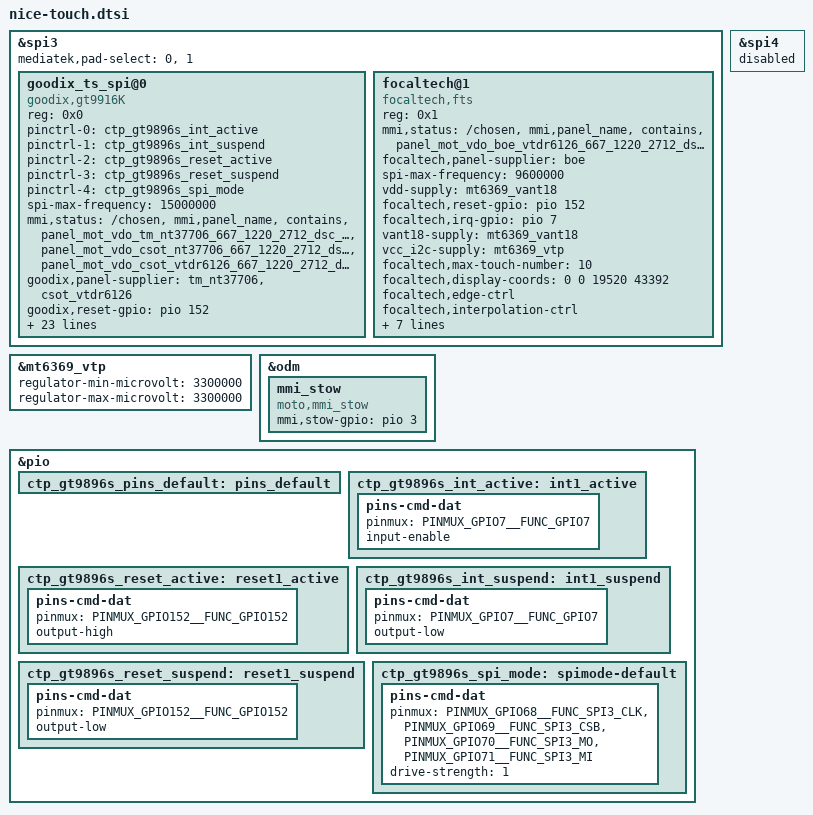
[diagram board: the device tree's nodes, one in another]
// SPDX-License-Identifier: (GPL-2.0 OR MIT)
/*
 * Copyright (C) 2020 MediaTek Inc.
 */

/* TOUCH start */
&spi3 {
	status = "okay";
	#address-cells = <1>;
	#size-cells = <0>;
	mediatek,pad-select = <0>, <1>;

	goodix_ts_spi@0 {
		status = "okay";
		compatible = "goodix,gt9916K";
		reg = <0x0>;
		pinctrl-names = "pmx_ts_active", "pmx_ts_suspend", "stylus_clk_active", "stylus_clk_suspend","gt9916_spi_mode";
		pinctrl-0 = <&ctp_gt9896s_int_active>;
		pinctrl-1 = <&ctp_gt9896s_int_suspend>;
		pinctrl-2 = <&ctp_gt9896s_reset_active>;
		pinctrl-3 = <&ctp_gt9896s_reset_suspend>;
		pinctrl-4 = <&ctp_gt9896s_spi_mode>;
		spi-max-frequency = <15000000>;  /* 4800000,9600000,15000000,19200000 */
		mmi,status = "/chosen","mmi,panel_name","contains","panel_mot_vdo_tm_nt37706_667_1220_2712_dsc_dphy_nice","panel_mot_vdo_csot_nt37706_667_1220_2712_dsc_dphy_nice","panel_mot_vdo_csot_vtdr6126_667_1220_2712_dsc_dphy_nice";
		goodix,panel-supplier = "tm_nt37706","csot_vtdr6126";
		goodix,reset-gpio = <&pio 152 0x0>;
		goodix,irq-gpio = <&pio 7 0x2002>;
		goodix,avdd-name = "vtp";
//		goodix,avdd-gpio = <&pio 189 0x0>;
		vtp-supply = <&mt6369_vtp>;
		goodix,iovdd-name = "vant18";
//		goodix,iovdd-gpio = <&pio 114 0x0>;
		vant18-supply = <&mt6369_vant18>;
		goodix,irq-flags = <0x2002>; /* 1:trigger rising, 2:trigger falling;*/
		goodix,panel-max-id = <10>;
		goodix,panel-max-x = <19520>;
		goodix,panel-max-y = <43392>;
		goodix,panel-max-w = <256>;
		goodix,panel-max-p = <256>;
		goodix,edge-ctrl;
		goodix,sample-ctrl;
		goodix,interpolation-ctrl;
		goodix,gesture-wait-pm;
		goodix,stowed-mode-ctrl;
		goodix,pocket-mode-ctrl;
		/*goodix,config-name = "goodix_gt9916k_cfg_group.bin";
		goodix,firmware-name = "goodix_gt9916k_firmware.bin";*/
		mmi,enable-gestures;
		mmi,power-off-suspend;
		mmi,usb-charger-detection;
		mmi,supported_gesture_type = <0x07>;
		mmi,resolution_boost = <16>;
		mtk-charger = <&mt6375_chg>;
	};

	focaltech@1{
		status = "okay";
		compatible = "focaltech,fts";
		reg = <0x1>;
		mmi,status = "/chosen","mmi,panel_name","contains","panel_mot_vdo_boe_vtdr6126_667_1220_2712_dsc_dphy_nice";
		focaltech,panel-supplier = "boe";
		spi-max-frequency = <9600000>;
//		focaltech,vdd-gpio = <&pio 183 0x0>;
		vdd-supply= <&mt6369_vant18>;
		focaltech,reset-gpio = <&pio 152 0x0>;
		focaltech,irq-gpio = <&pio 7 0x2002>;
		vant18-supply = <&mt6369_vant18>;
//		vtp-supply = <&mt6369_vtp>;
		vcc_i2c-supply = <&mt6369_vtp>;
		focaltech,max-touch-number = <10>;
		focaltech,display-coords =  <0 0 19520 43392>;
		focaltech,edge-ctrl;
		focaltech,interpolation-ctrl;
		focaltech,sample-ctrl;
		fts,pocket-mode-ctrl;
		pinctrl-names = "pmx_ts_active", "pmx_ts_suspend", "pmx_ts_release";
		pinctrl-0 = <&ctp_gt9896s_int_active>;
		pinctrl-1 = <&ctp_gt9896s_int_suspend>;
		//panel = <&mot_tm_icna3508_ft3683g_667_1080x2400_dsc_vid &mot_boe_vtdr6130a_ft3683g_667_1080x2400_dsc_cmd>;
		//mmi,usb-charger-detection;
		mmi,enable-gestures;
		mmi,supported_gesture_type = <0x07>;
		focaltech,stowed-mode-ctrl;
	};
};

&mt6369_vtp {
	regulator-min-microvolt = <3300000>;
	regulator-max-microvolt = <3300000>;
};

&odm {
	mmi_stow: mmi_stow {
		compatible = "moto,mmi_stow";
		mmi,stow-gpio = <&pio 3 0x0>;
	};
};

&spi4 {
	status = "disabled";
};

&pio {
	ctp_gt9896s_pins_default: pins_default {
	};
	ctp_gt9896s_int_active: int1_active {
		pins-cmd-dat {
			pinmux = <PINMUX_GPIO7__FUNC_GPIO7>;
			input-enable;
		};
	};
	ctp_gt9896s_reset_active: reset1_active {
		pins-cmd-dat {
			pinmux = <PINMUX_GPIO152__FUNC_GPIO152>;
			output-high;
		};
	};
	ctp_gt9896s_int_suspend: int1_suspend {
		pins-cmd-dat {
			pinmux = <PINMUX_GPIO7__FUNC_GPIO7>;
			output-low;
		};
	};
	ctp_gt9896s_reset_suspend: reset1_suspend {
		pins-cmd-dat {
			pinmux = <PINMUX_GPIO152__FUNC_GPIO152>;
			output-low;
		};
	};
	ctp_gt9896s_spi_mode: spimode-default {
		pins-cmd-dat {
			pinmux = <PINMUX_GPIO68__FUNC_SPI3_CLK>,
				<PINMUX_GPIO69__FUNC_SPI3_CSB>,
				<PINMUX_GPIO70__FUNC_SPI3_MO>,
				<PINMUX_GPIO71__FUNC_SPI3_MI>;
			drive-strength = <1>;
		};
	};


};
/* TOUCH end */
